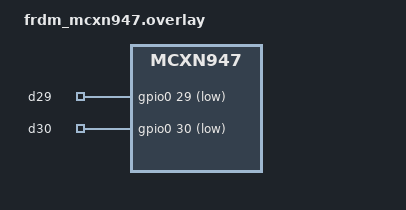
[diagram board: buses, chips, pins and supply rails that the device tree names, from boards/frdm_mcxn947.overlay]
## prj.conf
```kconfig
CONFIG_CUSTOM_BUTTON=y
CONFIG_LOG=y
CONFIG_LOG_DEFAULT_LEVEL=4
```

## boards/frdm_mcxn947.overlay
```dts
/ {
    aliases {
        my-button-1 = &button_1;
        my-button-2 = &button_2;
    };

    custom-buttons {
        button_1: custom_button_1 {
            compatible = "custom,button";
            pin = <&d29>;
        };

        button_2: custom_button_2 {
            compatible = "custom,button";
            pin = <&d30>;
        };
    };

    gpio-keys {
        compatible = "gpio-keys";
        polling-mode;

        d29: gpio29 {
            gpios = <&gpio0 29 (GPIO_ACTIVE_LOW | GPIO_PULL_UP)>;
        };

        d30: gpio30 {
            gpios = <&gpio0 30 (GPIO_ACTIVE_LOW | GPIO_PULL_UP)>;
        };
    };
};
```

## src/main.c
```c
#include <stdio.h>
#include <zephyr/kernel.h>

#include "button.h"

// Settings
static const int32_t sleep_time_ms = 50;
static const struct device *btn_1 = DEVICE_DT_GET(DT_ALIAS(my_button_1));
static const struct device *btn_2 = DEVICE_DT_GET(DT_ALIAS(my_button_2));

int main(void)
{
    int ret;
    uint8_t state_1;
    uint8_t state_2;

    // Make sure button was initialized
    if (!(device_is_ready(btn_1) && device_is_ready(btn_2))) {
        printk("Error: buttons are not ready\r\n");
        return 0;
    }

    // Get API from one of the buttons
    const struct button_api *btn_api = (const struct button_api *)btn_1->api;

    // Do forever
    while (1) {

        // Poll button 1 state
        ret = btn_api->get(btn_1, &state_1);
        if (ret < 0) {
            printk("Error (%d): failed to read button 1 pin\r\n", ret);
            continue;
        }

        // Poll button 2 state
        ret = btn_api->get(btn_2, &state_2);
        if (ret < 0) {
            printk("Error (%d): failed to read button 2 pin\r\n", ret);
            continue;
        }

        printk("%u %u\r\n", state_1, state_2);

        k_msleep(sleep_time_ms);
    }

    return 0;
}
```
